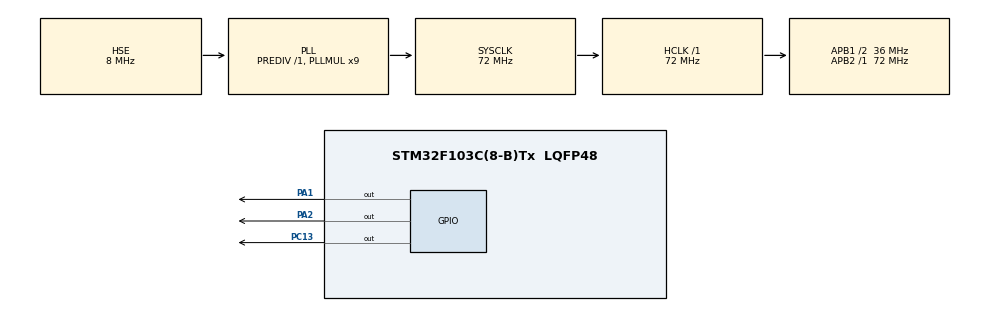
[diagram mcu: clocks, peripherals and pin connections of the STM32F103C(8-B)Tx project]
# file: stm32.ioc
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FREERTOS.Tasks01=defaultTask,0,128,StartDefaultTask,Default,NULL,Dynamic,NULL,NULL
Mcu.Family=STM32F1
Mcu.Name=STM32F103C(8-B)Tx
Mcu.Package=LQFP48
NVIC.PriorityGroup=NVIC_PRIORITYGROUP_4
NVIC.TIM4_IRQn=true\:15\:0\:false\:false\:true\:false\:false\:true\:true
NVIC.TimeBase=TIM4_IRQn
NVIC.TimeBaseIP=TIM4
PA1.Signal=GPIO_Output
PA13.Mode=Serial_Wire
PA13.Signal=SYS_JTMS-SWDIO
PA14.Mode=Serial_Wire
PA14.Signal=SYS_JTCK-SWCLK
PA2.Signal=GPIO_Output
PC13-TAMPER-RTC.Signal=GPIO_Output
PD0-OSC_IN.Mode=HSE-External-Oscillator
PD0-OSC_IN.Signal=RCC_OSC_IN
PD1-OSC_OUT.Mode=HSE-External-Oscillator
PD1-OSC_OUT.Signal=RCC_OSC_OUT
ProjectManager.HeapSize=0x200
ProjectManager.StackSize=0x400
ProjectManager.TargetToolchain=MDK-ARM V5.32
RCC.AHBFreq_Value=72000000
RCC.APB1CLKDivider=RCC_HCLK_DIV2
RCC.APB1Freq_Value=36000000
RCC.APB1TimFreq_Value=72000000
RCC.APB2Freq_Value=72000000
RCC.APB2TimFreq_Value=72000000
RCC.HCLKFreq_Value=72000000
RCC.PLLMUL=RCC_PLL_MUL9
RCC.PLLSourceVirtual=RCC_PLLSOURCE_HSE
RCC.SYSCLKFreq_VALUE=72000000
RCC.SYSCLKSource=RCC_SYSCLKSOURCE_PLLCLK
RCC.USBFreq_Value=72000000
VP_FREERTOS_VS_CMSIS_V1.Mode=CMSIS_V1
VP_SYS_VS_tim4.Mode=TIM4
board=custom

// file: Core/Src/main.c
/* USER CODE BEGIN Header */
/**
  ******************************************************************************
  * @file           : main.c
  * @brief          : Main program body
  ******************************************************************************
  * @attention
  *
  * Copyright (c) 2026 STMicroelectronics.
  * All rights reserved.
  *
  * This software is licensed under terms that can be found in the LICENSE file
  * in the root directory of this software component.
  * If no LICENSE file comes with this software, it is provided AS-IS.
  *
  ******************************************************************************
  */
/* USER CODE END Header */
#include "main.h"
#include "cmsis_os.h"

/* USER CODE BEGIN PTD */
/* USER CODE BEGIN PTD */
typedef struct {
    GPIO_TypeDef* port;
    uint16_t pin;
    float freq_hz;
} LedConfig_t;
/* USER CODE END PTD */
/* USER CODE END PTD */

osThreadId defaultTaskHandle;
/* USER CODE BEGIN PV */
/* USER CODE BEGIN PV */
// Khai báo c?u hình cho 3 LED (0.1Hz, 1Hz, 10Hz)
LedConfig_t led1 = {GPIOC, GPIO_PIN_13, 0.1f}; // LED 1: 0.1Hz (5000ms b?t, 5000ms t?t)
LedConfig_t led2 = {GPIOA, GPIO_PIN_1,  1.0f}; // LED 2: 1Hz (500ms b?t, 500ms t?t)
LedConfig_t led3 = {GPIOA, GPIO_PIN_2, 10.0f}; // LED 3: 10Hz (50ms b?t, 50ms t?t)
/* USER CODE END PV */
/* USER CODE END PV */

void SystemClock_Config(void);
static void MX_GPIO_Init(void);
void StartDefaultTask(void const * argument);

/* USER CODE BEGIN 0 */
/* USER CODE BEGIN 0 */
void LedBlinkTask(void *pvParameters)
{
    LedConfig_t *cfg = (LedConfig_t *)pvParameters;

    // Tính th?i gian tr? m?i l?n toggle (n?a chu k?) tính theo ms
    uint32_t delay_ms = (uint32_t)(1000.0f / (2.0f * cfg->freq_hz));
    TickType_t xDelayTicks = pdMS_TO_TICKS(delay_ms);

    while (1)
    {
        HAL_GPIO_TogglePin(cfg->port, cfg->pin);
        vTaskDelay(xDelayTicks);
    }
}
/* USER CODE END 0 */
/* USER CODE END 0 */

int main(void)
{

  /* MCU Configuration--------------------------------------------------------*/

  /* Reset of all peripherals, Initializes the Flash interface and the Systick. */
  HAL_Init();

  /* Configure the system clock */
  SystemClock_Config();

  /* Initialize all configured peripherals */
  MX_GPIO_Init();
  /* USER CODE BEGIN 2 */
xTaskCreate(LedBlinkTask, "LED_0.1Hz", 128, (void *)&led1, 1, NULL);
  xTaskCreate(LedBlinkTask, "LED_1Hz",   128, (void *)&led2, 1, NULL);
  xTaskCreate(LedBlinkTask, "LED_10Hz",  128, (void *)&led3, 1, NULL);
  vTaskStartScheduler();
  /* USERxTaskCreate(LedBlinkTask, "LED_0.1Hz", 128, (void *)&led1, 1, NULL);
  xTaskCreate(LedBlinkTask, "LED_1Hz",   128, (void *)&led2, 1, NULL);
  xTaskCreate(LedBlinkTask, "LED_10Hz",  128, (void *)&led3, 1, NULL);
 CODE END 2 */

  /* Create the thread(s) */
  /* definition and creation of defaultTask */
  osThreadDef(defaultTask, StartDefaultTask, osPriorityNormal, 0, 128);
  defaultTaskHandle = osThreadCreate(osThread(defaultTask), NULL);

  /* Start scheduler */
  osKernelStart();

  /* We should never get here as control is now taken by the scheduler */

  /* Infinite loop */
  while (1)
  {

  }
}

void SystemClock_Config(void)
{
  RCC_OscInitTypeDef RCC_OscInitStruct = {0};
  RCC_ClkInitTypeDef RCC_ClkInitStruct = {0};

  /** Initializes the RCC Oscillators according to the specified parameters
  * in the RCC_OscInitTypeDef structure.
  */
  RCC_OscInitStruct.OscillatorType = RCC_OSCILLATORTYPE_HSE;
  RCC_OscInitStruct.HSEState = RCC_HSE_ON;
  RCC_OscInitStruct.HSEPredivValue = RCC_HSE_PREDIV_DIV1;
  RCC_OscInitStruct.HSIState = RCC_HSI_ON;
  RCC_OscInitStruct.PLL.PLLState = RCC_PLL_ON;
  RCC_OscInitStruct.PLL.PLLSource = RCC_PLLSOURCE_HSE;
  RCC_OscInitStruct.PLL.PLLMUL = RCC_PLL_MUL9;
  if (HAL_RCC_OscConfig(&RCC_OscInitStruct) != HAL_OK)
  {
    Error_Handler();
  }

  /** Initializes the CPU, AHB and APB buses clocks
  */
  RCC_ClkInitStruct.ClockType = RCC_CLOCKTYPE_HCLK|RCC_CLOCKTYPE_SYSCLK
                              |RCC_CLOCKTYPE_PCLK1|RCC_CLOCKTYPE_PCLK2;
  RCC_ClkInitStruct.SYSCLKSource = RCC_SYSCLKSOURCE_PLLCLK;
  RCC_ClkInitStruct.AHBCLKDivider = RCC_SYSCLK_DIV1;
  RCC_ClkInitStruct.APB1CLKDivider = RCC_HCLK_DIV2;
  RCC_ClkInitStruct.APB2CLKDivider = RCC_HCLK_DIV1;

  if (HAL_RCC_ClockConfig(&RCC_ClkInitStruct, FLASH_LATENCY_2) != HAL_OK)
  {
    Error_Handler();
  }
}

static void MX_GPIO_Init(void)
{

  /* GPIO Ports Clock Enable */
  __HAL_RCC_GPIOD_CLK_ENABLE();
  __HAL_RCC_GPIOA_CLK_ENABLE();

}

void StartDefaultTask(void const * argument)
{
  for(;;)
  {
    osDelay(1);
  }
}

void HAL_TIM_PeriodElapsedCallback(TIM_HandleTypeDef *htim)
{
  if (htim->Instance == TIM4)
  {
    HAL_IncTick();
  }
}

void Error_Handler(void)
{
  __disable_irq();
  while (1)
  {
  }
}
